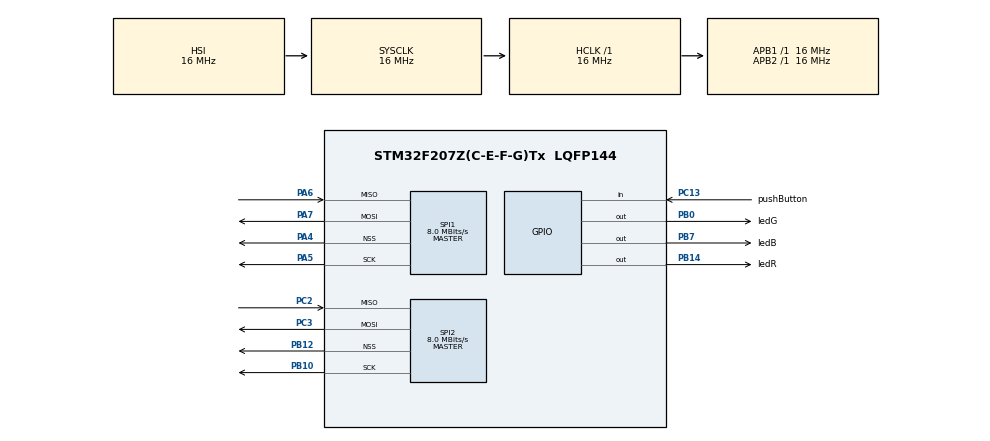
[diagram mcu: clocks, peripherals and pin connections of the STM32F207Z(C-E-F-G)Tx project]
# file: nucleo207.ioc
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Dma.Request0=SPI1_RX
Dma.Request1=SPI1_TX
Dma.Request2=SPI2_RX
Dma.Request3=SPI2_TX
Dma.SPI1_RX.0.Direction=DMA_PERIPH_TO_MEMORY
Dma.SPI1_RX.0.FIFOMode=DMA_FIFOMODE_ENABLE
Dma.SPI1_RX.0.FIFOThreshold=DMA_FIFO_THRESHOLD_FULL
Dma.SPI1_RX.0.Instance=DMA2_Stream0
Dma.SPI1_RX.0.MemBurst=DMA_MBURST_SINGLE
Dma.SPI1_RX.0.MemDataAlignment=DMA_MDATAALIGN_BYTE
Dma.SPI1_RX.0.MemInc=DMA_MINC_ENABLE
Dma.SPI1_RX.0.Mode=DMA_NORMAL
Dma.SPI1_RX.0.PeriphBurst=DMA_PBURST_SINGLE
Dma.SPI1_RX.0.PeriphDataAlignment=DMA_PDATAALIGN_BYTE
Dma.SPI1_RX.0.PeriphInc=DMA_PINC_DISABLE
Dma.SPI1_RX.0.Priority=DMA_PRIORITY_LOW
Dma.SPI1_TX.1.Direction=DMA_MEMORY_TO_PERIPH
Dma.SPI1_TX.1.FIFOMode=DMA_FIFOMODE_ENABLE
Dma.SPI1_TX.1.FIFOThreshold=DMA_FIFO_THRESHOLD_FULL
Dma.SPI1_TX.1.Instance=DMA2_Stream3
Dma.SPI1_TX.1.MemBurst=DMA_MBURST_SINGLE
Dma.SPI1_TX.1.MemDataAlignment=DMA_MDATAALIGN_BYTE
Dma.SPI1_TX.1.MemInc=DMA_MINC_ENABLE
Dma.SPI1_TX.1.Mode=DMA_NORMAL
Dma.SPI1_TX.1.PeriphBurst=DMA_PBURST_SINGLE
Dma.SPI1_TX.1.PeriphDataAlignment=DMA_PDATAALIGN_BYTE
Dma.SPI1_TX.1.PeriphInc=DMA_PINC_DISABLE
Dma.SPI1_TX.1.Priority=DMA_PRIORITY_LOW
Dma.SPI2_RX.2.Direction=DMA_PERIPH_TO_MEMORY
Dma.SPI2_RX.2.FIFOMode=DMA_FIFOMODE_ENABLE
Dma.SPI2_RX.2.FIFOThreshold=DMA_FIFO_THRESHOLD_FULL
Dma.SPI2_RX.2.Instance=DMA1_Stream3
Dma.SPI2_RX.2.MemBurst=DMA_MBURST_SINGLE
Dma.SPI2_RX.2.MemDataAlignment=DMA_MDATAALIGN_BYTE
Dma.SPI2_RX.2.MemInc=DMA_MINC_ENABLE
Dma.SPI2_RX.2.Mode=DMA_NORMAL
Dma.SPI2_RX.2.PeriphBurst=DMA_PBURST_SINGLE
Dma.SPI2_RX.2.PeriphDataAlignment=DMA_PDATAALIGN_BYTE
Dma.SPI2_RX.2.PeriphInc=DMA_PINC_DISABLE
Dma.SPI2_RX.2.Priority=DMA_PRIORITY_LOW
Dma.SPI2_TX.3.Direction=DMA_MEMORY_TO_PERIPH
Dma.SPI2_TX.3.FIFOMode=DMA_FIFOMODE_ENABLE
Dma.SPI2_TX.3.FIFOThreshold=DMA_FIFO_THRESHOLD_FULL
Dma.SPI2_TX.3.Instance=DMA1_Stream4
Dma.SPI2_TX.3.MemBurst=DMA_MBURST_SINGLE
Dma.SPI2_TX.3.MemDataAlignment=DMA_MDATAALIGN_BYTE
Dma.SPI2_TX.3.MemInc=DMA_MINC_ENABLE
Dma.SPI2_TX.3.Mode=DMA_NORMAL
Dma.SPI2_TX.3.PeriphBurst=DMA_PBURST_SINGLE
Dma.SPI2_TX.3.PeriphDataAlignment=DMA_PDATAALIGN_BYTE
Dma.SPI2_TX.3.PeriphInc=DMA_PINC_DISABLE
Dma.SPI2_TX.3.Priority=DMA_PRIORITY_LOW
FREERTOS.Tasks01=defaultTask,0,128,StartDefaultTask,Default,NULL
Mcu.Family=STM32F2
Mcu.Name=STM32F207Z(C-E-F-G)Tx
Mcu.Package=LQFP144
NVIC.DMA1_Stream3_IRQn=true\:5\:0\:false\:false\:true\:true\:false\:true
NVIC.DMA1_Stream4_IRQn=true\:5\:0\:false\:false\:true\:true\:false\:true
NVIC.DMA2_Stream0_IRQn=true\:5\:0\:false\:false\:true\:true\:false\:true
NVIC.DMA2_Stream3_IRQn=true\:5\:0\:false\:false\:true\:true\:false\:true
NVIC.PriorityGroup=NVIC_PRIORITYGROUP_4
NVIC.TIM1_UP_TIM10_IRQn=true\:0\:0\:false\:false\:true\:false\:false\:true
NVIC.TimeBase=TIM1_UP_TIM10_IRQn
NVIC.TimeBaseIP=TIM1
PA4.Mode=NSS_Signal_Hard_Output
PA4.Signal=SPI1_NSS
PA5.Mode=Full_Duplex_Master
PA5.Signal=SPI1_SCK
PA6.Mode=Full_Duplex_Master
PA6.Signal=SPI1_MISO
PA7.Mode=Full_Duplex_Master
PA7.Signal=SPI1_MOSI
PB0.GPIO_Label=ledG
PB0.Signal=GPIO_Output
PB10.Mode=Full_Duplex_Master
PB10.Signal=SPI2_SCK
PB12.Mode=NSS_Signal_Hard_Output
PB12.Signal=SPI2_NSS
PB14.GPIO_Label=ledR
PB14.Signal=GPIO_Output
PB7.GPIO_Label=ledB
PB7.Signal=GPIO_Output
PC13.GPIO_Label=pushButton
PC13.Signal=GPIO_Input
PC2.Mode=Full_Duplex_Master
PC2.Signal=SPI2_MISO
PC3.Mode=Full_Duplex_Master
PC3.Signal=SPI2_MOSI
ProjectManager.HeapSize=0x200
ProjectManager.StackSize=0x400
ProjectManager.TargetToolchain=Makefile
RCC.48MHZClocksFreq_Value=48000000
RCC.AHBFreq_Value=16000000
RCC.APB1Freq_Value=16000000
RCC.APB2Freq_Value=16000000
RCC.CortexFreq_Value=16000000
RCC.HSE_VALUE=25000000
RCC.HSI_VALUE=16000000
RCC.LSE_VALUE=32768
RCC.SYSCLKFreq_VALUE=16000000
RCC.VCOOutputFreq_Value=192000000
SPI1.CalculateBaudRate=8.0 MBits/s
SPI1.Direction=SPI_DIRECTION_2LINES
SPI1.Mode=SPI_MODE_MASTER
SPI1.VirtualNSS=VM_NSSHARD
SPI1.VirtualType=VM_MASTER
SPI2.CalculateBaudRate=8.0 MBits/s
SPI2.Direction=SPI_DIRECTION_2LINES
SPI2.Mode=SPI_MODE_MASTER
SPI2.VirtualNSS=VM_NSSHARD
SPI2.VirtualType=VM_MASTER
VP_FREERTOS_VS_CMSIS_V1.Mode=CMSIS_V1
VP_SYS_VS_tim1.Mode=TIM1
board=custom

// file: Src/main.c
/* USER CODE BEGIN Header */
/**
  ******************************************************************************
  * @file           : main.c
  * @brief          : Main program body
  ******************************************************************************
  * @attention
  *
  * <h2><center>&copy; Copyright (c) 2020 STMicroelectronics.
  * All rights reserved.</center></h2>
  *
  * This software component is licensed by ST under BSD 3-Clause license,
  * the "License"; You may not use this file except in compliance with the
  * License. You may obtain a copy of the License at:
  *                        opensource.org/licenses/BSD-3-Clause
  *
  ******************************************************************************
  */
/* USER CODE END Header */

#include "main.h"
#include "cmsis_os.h"

/* USER CODE BEGIN Includes */
#include "button.h"
#include "led.h"
/* USER CODE END Includes */

SPI_HandleTypeDef hspi1;
SPI_HandleTypeDef hspi2;
DMA_HandleTypeDef hdma_spi1_rx;
DMA_HandleTypeDef hdma_spi1_tx;
DMA_HandleTypeDef hdma_spi2_rx;
DMA_HandleTypeDef hdma_spi2_tx;

osThreadId defaultTaskHandle;

void SystemClock_Config(void);
static void MX_GPIO_Init(void);
static void MX_DMA_Init(void);
static void MX_SPI1_Init(void);
static void MX_SPI2_Init(void);
void StartDefaultTask(void const * argument);

int main(void)
{

  /* MCU Configuration--------------------------------------------------------*/

  /* Reset of all peripherals, Initializes the Flash interface and the Systick. */
  HAL_Init();

  /* Configure the system clock */
  SystemClock_Config();

  /* Initialize all configured peripherals */
  MX_GPIO_Init();
  MX_DMA_Init();
  MX_SPI1_Init();
  MX_SPI2_Init();

  /* Create the thread(s) */
  /* definition and creation of defaultTask */
  osThreadDef(defaultTask, StartDefaultTask, osPriorityNormal, 0, 128);
  defaultTaskHandle = osThreadCreate(osThread(defaultTask), NULL);

  /* Start scheduler */
  osKernelStart();

  /* We should never get here as control is now taken by the scheduler */
  /* Infinite loop */
  while (1)
  {

  }
}

void SystemClock_Config(void)
{
  RCC_OscInitTypeDef RCC_OscInitStruct = {0};
  RCC_ClkInitTypeDef RCC_ClkInitStruct = {0};

  /** Initializes the CPU, AHB and APB busses clocks
  */
  RCC_OscInitStruct.OscillatorType = RCC_OSCILLATORTYPE_HSI;
  RCC_OscInitStruct.HSIState = RCC_HSI_ON;
  RCC_OscInitStruct.HSICalibrationValue = RCC_HSICALIBRATION_DEFAULT;
  RCC_OscInitStruct.PLL.PLLState = RCC_PLL_NONE;
  if (HAL_RCC_OscConfig(&RCC_OscInitStruct) != HAL_OK)
  {
    Error_Handler();
  }
  /** Initializes the CPU, AHB and APB busses clocks
  */
  RCC_ClkInitStruct.ClockType = RCC_CLOCKTYPE_HCLK|RCC_CLOCKTYPE_SYSCLK
                              |RCC_CLOCKTYPE_PCLK1|RCC_CLOCKTYPE_PCLK2;
  RCC_ClkInitStruct.SYSCLKSource = RCC_SYSCLKSOURCE_HSI;
  RCC_ClkInitStruct.AHBCLKDivider = RCC_SYSCLK_DIV1;
  RCC_ClkInitStruct.APB1CLKDivider = RCC_HCLK_DIV1;
  RCC_ClkInitStruct.APB2CLKDivider = RCC_HCLK_DIV1;

  if (HAL_RCC_ClockConfig(&RCC_ClkInitStruct, FLASH_LATENCY_0) != HAL_OK)
  {
    Error_Handler();
  }
}

static void MX_SPI1_Init(void)
{

  /* SPI1 parameter configuration*/
  hspi1.Instance = SPI1;
  hspi1.Init.Mode = SPI_MODE_MASTER;
  hspi1.Init.Direction = SPI_DIRECTION_2LINES;
  hspi1.Init.DataSize = SPI_DATASIZE_8BIT;
  hspi1.Init.CLKPolarity = SPI_POLARITY_LOW;
  hspi1.Init.CLKPhase = SPI_PHASE_1EDGE;
  hspi1.Init.NSS = SPI_NSS_HARD_OUTPUT;
  hspi1.Init.BaudRatePrescaler = SPI_BAUDRATEPRESCALER_2;
  hspi1.Init.FirstBit = SPI_FIRSTBIT_MSB;
  hspi1.Init.TIMode = SPI_TIMODE_DISABLE;
  hspi1.Init.CRCCalculation = SPI_CRCCALCULATION_DISABLE;
  hspi1.Init.CRCPolynomial = 10;
  if (HAL_SPI_Init(&hspi1) != HAL_OK)
  {
    Error_Handler();
  }

}

static void MX_SPI2_Init(void)
{

  /* SPI2 parameter configuration*/
  hspi2.Instance = SPI2;
  hspi2.Init.Mode = SPI_MODE_MASTER;
  hspi2.Init.Direction = SPI_DIRECTION_2LINES;
  hspi2.Init.DataSize = SPI_DATASIZE_8BIT;
  hspi2.Init.CLKPolarity = SPI_POLARITY_LOW;
  hspi2.Init.CLKPhase = SPI_PHASE_1EDGE;
  hspi2.Init.NSS = SPI_NSS_HARD_OUTPUT;
  hspi2.Init.BaudRatePrescaler = SPI_BAUDRATEPRESCALER_2;
  hspi2.Init.FirstBit = SPI_FIRSTBIT_MSB;
  hspi2.Init.TIMode = SPI_TIMODE_DISABLE;
  hspi2.Init.CRCCalculation = SPI_CRCCALCULATION_DISABLE;
  hspi2.Init.CRCPolynomial = 10;
  if (HAL_SPI_Init(&hspi2) != HAL_OK)
  {
    Error_Handler();
  }

}

static void MX_DMA_Init(void)
{

  /* DMA controller clock enable */
  __HAL_RCC_DMA2_CLK_ENABLE();
  __HAL_RCC_DMA1_CLK_ENABLE();

  /* DMA interrupt init */
  /* DMA1_Stream3_IRQn interrupt configuration */
  HAL_NVIC_SetPriority(DMA1_Stream3_IRQn, 5, 0);
  HAL_NVIC_EnableIRQ(DMA1_Stream3_IRQn);
  /* DMA1_Stream4_IRQn interrupt configuration */
  HAL_NVIC_SetPriority(DMA1_Stream4_IRQn, 5, 0);
  HAL_NVIC_EnableIRQ(DMA1_Stream4_IRQn);
  /* DMA2_Stream0_IRQn interrupt configuration */
  HAL_NVIC_SetPriority(DMA2_Stream0_IRQn, 5, 0);
  HAL_NVIC_EnableIRQ(DMA2_Stream0_IRQn);
  /* DMA2_Stream3_IRQn interrupt configuration */
  HAL_NVIC_SetPriority(DMA2_Stream3_IRQn, 5, 0);
  HAL_NVIC_EnableIRQ(DMA2_Stream3_IRQn);

}

static void MX_GPIO_Init(void)
{
  GPIO_InitTypeDef GPIO_InitStruct = {0};

  /* GPIO Ports Clock Enable */
  __HAL_RCC_GPIOC_CLK_ENABLE();
  __HAL_RCC_GPIOA_CLK_ENABLE();
  __HAL_RCC_GPIOB_CLK_ENABLE();

  /*Configure GPIO pin Output Level */
  HAL_GPIO_WritePin(GPIOB, ledG_Pin|ledR_Pin|ledB_Pin, GPIO_PIN_RESET);

  /*Configure GPIO pin : pushButton_Pin */
  GPIO_InitStruct.Pin = pushButton_Pin;
  GPIO_InitStruct.Mode = GPIO_MODE_INPUT;
  GPIO_InitStruct.Pull = GPIO_NOPULL;
  HAL_GPIO_Init(pushButton_GPIO_Port, &GPIO_InitStruct);

  /*Configure GPIO pins : ledG_Pin ledR_Pin ledB_Pin */
  GPIO_InitStruct.Pin = ledG_Pin|ledR_Pin|ledB_Pin;
  GPIO_InitStruct.Mode = GPIO_MODE_OUTPUT_PP;
  GPIO_InitStruct.Pull = GPIO_NOPULL;
  GPIO_InitStruct.Speed = GPIO_SPEED_FREQ_LOW;
  HAL_GPIO_Init(GPIOB, &GPIO_InitStruct);

}

void StartDefaultTask(void const * argument)
{
  /* USER CODE BEGIN 5 */
  /* Infinite loop */

  for(;;)
  {

    while(blink())
    {
      osDelay(10);
    }

    osThreadTerminate(defaultTaskHandle);
  }
  /* USER CODE END 5 */
}

 /**
  * @brief  Period elapsed callback in non blocking mode
  * @note   This function is called  when TIM1 interrupt took place, inside
  * HAL_TIM_IRQHandler(). It makes a direct call to HAL_IncTick() to increment
  * a global variable "uwTick" used as application time base.
  * @param  htim : TIM handle
  * @retval None
  */
void HAL_TIM_PeriodElapsedCallback(TIM_HandleTypeDef *htim)
{
  /* USER CODE BEGIN Callback 0 */
  if (htim->Instance == TIM1) {
    button_updateButton();
  }
  /* USER CODE END Callback 0 */
  if (htim->Instance == TIM1) {
    HAL_IncTick();
  }
}

void Error_Handler(void)
{
}

/************************ (C) COPYRIGHT STMicroelectronics *****END OF FILE****/
